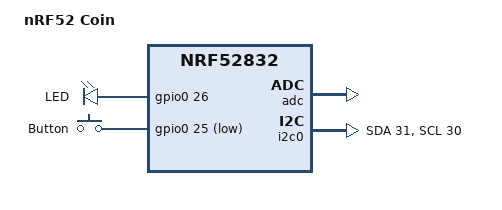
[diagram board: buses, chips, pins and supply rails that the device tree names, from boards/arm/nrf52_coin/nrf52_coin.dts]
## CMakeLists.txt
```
cmake_minimum_required(VERSION 3.8.2)

get_filename_component( ENV{ZEPHYR_BASE} "${CMAKE_SOURCE_DIR}/../zephyr" ABSOLUTE)
set( ENV{BOARD} nrf52_coin )
set( BOARD_ROOT ${CMAKE_SOURCE_DIR} )
set( ENV{ZEPHYR_TOOLCHAIN_VARIANT} zephyr )
set( ENV{ZEPHYR_SDK_INSTALL_DIR} /opt/zephyr-sdk/ )

include($ENV{ZEPHYR_BASE}/cmake/app/boilerplate.cmake NO_POLICY_SCOPE)

project(coin)
zephyr_include_directories(
  $ENV{ZEPHYR_BASE}/subsys/bluetooth/host
)


target_sources(app PRIVATE src/main.c src/kx022.c)
```

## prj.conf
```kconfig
# Incresed stack due to settings API usage
CONFIG_SYSTEM_WORKQUEUE_STACK_SIZE=2048

CONFIG_BT=y
CONFIG_BT_DEBUG_LOG=y
CONFIG_BT_SMP=y
CONFIG_BT_SIGNING=y
CONFIG_BT_PERIPHERAL=y
CONFIG_BT_GATT_DIS=y
CONFIG_BT_ATT_PREPARE_COUNT=5
CONFIG_BT_PRIVACY=y
CONFIG_BT_DEVICE_NAME="Zephyr"
CONFIG_BT_DEVICE_APPEARANCE=833

CONFIG_BT_SETTINGS=y
CONFIG_FLASH=y
CONFIG_FLASH_PAGE_LAYOUT=y
CONFIG_FLASH_MAP=y
CONFIG_FCB=y
CONFIG_SETTINGS=y
CONFIG_SETTINGS_FCB=y

CONFIG_I2C=y
CONFIG_I2C_0=y

CONFIG_BT_LL_SW_LEGACY=y

CONFIG_HAS_SEGGER_RTT=y
CONFIG_USE_SEGGER_RTT=y
CONFIG_RTT_CONSOLE=y
CONFIG_UART_CONSOLE=n
```

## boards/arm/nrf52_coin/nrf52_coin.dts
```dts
/*
 * Copyright (c) Maximilian Deubel
 *
 * SPDX-License-Identifier: Apache-2.0
 */

/dts-v1/;
#include <nordic/nrf52832_qfaa.dtsi>

/ {
	model = "nRF52 Coin";
	compatible = "maxd,nrf52_coin", "nordic,nrf52832-qfaa",
		     "nordic,nrf52832";

	chosen {
		zephyr,sram = &sram0;
		zephyr,flash = &flash0;
	};

	/* These aliases are provided for compatibility with samples */
	aliases {
		led0 = &led0;
		sw0 = &button0;
	};

	leds {
		compatible = "gpio-leds";
		led0: led_0 {
			gpios = <&gpio0 26 0>;
			label = "LED";
		};
	};

	buttons {
		compatible = "gpio-keys";
		button0: button_0 {
			gpios = <&gpio0 25 (GPIO_PUD_PULL_UP |
					    GPIO_INT_ACTIVE_LOW)>;
			label = "Button";
		};
	};
};

&adc {
	status ="okay";
};

&gpiote {
	status ="okay";
};

&gpio0 {
	status ="okay";
};

arduino_i2c: &i2c0 {
	status = "okay";
	sda-pin = <31>;
	scl-pin = <30>;
};

&flash0 {
	/*
	 * For more information, see:
	 * http://docs.zephyrproject.org/latest/guides/dts/index.html#flash-partitions
	 */
	partitions {
		compatible = "fixed-partitions";
		#address-cells = <1>;
		#size-cells = <1>;
		slot0_partition: partition@0 {
			label = "image-0";
			reg = <0x00000000 0x32000>;
		};

		storage_partition: partition@32000 {
			label = "storage";
			reg = <0x32000 0x00006000>;
		};
		/*
		 * REMEMBER TO UPDATE ADDRESS AND LENGTH IN prod/gen_bond.py
		 */
	};
};
```

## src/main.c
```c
#include <errno.h>
#include <zephyr.h>
#include <sys/printk.h>
#include <device.h>
#include <drivers/i2c.h>
#include <gpio.h>

#include <settings/settings.h>

#include <bluetooth/bluetooth.h>
#include <bluetooth/hci.h>
#include <bluetooth/conn.h>
#include <bluetooth/uuid.h>
#include <bluetooth/gatt.h>

#include <logging/log.h>

LOG_MODULE_REGISTER(app);

#include "kx022.h"

#define I2C_DEV "I2C_0"
#define LED_PORT DT_ALIAS_LED0_GPIOS_CONTROLLER
#define LED DT_ALIAS_LED0_GPIOS_PIN

static uint8_t batt_adv_bytes[] = {0x0f, 0x18, /* batt level UUID */
                                   0x00}; /* actual batt level */
static const struct bt_data ad[] = {
        BT_DATA_BYTES(BT_DATA_FLAGS, (BT_LE_AD_GENERAL | BT_LE_AD_NO_BREDR)),
        BT_DATA(BT_DATA_SVC_DATA16, batt_adv_bytes, sizeof(batt_adv_bytes))
};

static void bt_ready(int err) {
    if (err) {
        LOG_INF("Bluetooth init failed (err %d)", err);
        return;
    }

    LOG_INF("Bluetooth initialized");

    if (IS_ENABLED(CONFIG_SETTINGS)) {
        settings_load();
    }

    err = bt_le_adv_start(BT_LE_ADV_CONN_NAME, ad, ARRAY_SIZE(ad), NULL, 0);
    if (err) {
        LOG_INF("Advertising failed to start (err %d)", err);
        return;
    }

    LOG_INF("Advertising successfully started");
}

static u8_t led_state = 0;

static void kx022_int1(struct device *dev, struct gpio_callback *cb, u32_t pins) {
    ARG_UNUSED(dev);
    ARG_UNUSED(cb);
    ARG_UNUSED(pins);
    led_state = 1 - led_state;
    gpio_pin_write(dev, LED, led_state);
    LOG_INF("YEAH, the INT1 interrupt occurred.");
}

static struct gpio_callback kx022_int1_cb = {{0}};

void main(void) {
    struct device *i2c_dev = device_get_binding(I2C_DEV);
    if (!i2c_dev) {
        LOG_INF("I2C: Device driver not found.");
        return;
    }
    batt_adv_bytes[2] = kx022_verify_id(i2c_dev, KX022_ADDR_GND);
    LOG_INF("ID Verified? %d ", batt_adv_bytes[2]);
    kx022_init(i2c_dev, KX022_ADDR_GND);
    u8_t readout[6] = {0};
    while (1) {
        k_sleep(1000);
        kx022_read_acc(i2c_dev, KX022_ADDR_GND, readout);
        int16_t x = (readout[0] | (readout[1] << 8));
        int16_t y = (readout[2] | (readout[3] << 8));
        int16_t z = (readout[4] | (readout[5] << 8));
        x /= 409.6;
        y /= 409.6;
        z /= 409.6;
        LOG_INF("X: %d Y %d Z: %d ", x, y, z);
        //LOG_HEXDUMP_INF(readout, 6, "READOUT");
    }
}
```

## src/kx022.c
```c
#include "kx022.h"
#include "kx022_regs.h"

#include <logging/log.h>

LOG_MODULE_REGISTER(kx022);

void kx022_init(struct device *dev, u16_t addr) {
    // go into setup mode
    i2c_reg_write_byte(dev, addr, KX022_REG_CNTL1, 0);
    // set output data rate to 12.5Hz
    i2c_reg_write_byte(dev, addr, KX022_REG_ODCNTL, 0);
    // enable INT1 non-latching active-low
    i2c_reg_write_byte(dev, addr, KX022_REG_INC1, KX022_BIT_IEL1 | KX022_BIT_IEN1);
    // enable INT1 on data ready
    i2c_reg_write_byte(dev, addr, KX022_REG_INC4, KX022_BIT_DRDYI1);
    // set low-power (8-Bit resolution), sensitivity and enable sensor
    i2c_reg_write_byte(dev, addr, KX022_REG_CNTL1, KX022_BIT_PC1 | KX022_BIT_GSEL1 | KX022_BIT_RES);
    k_sleep(250);
}

bool kx022_verify_id(struct device *dev, u16_t addr) {
    u8_t id = 0;
    //read who-am-i value
    i2c_reg_read_byte(dev, addr, KX022_REG_Who_AM_I, &id);
    return KX022_WHO_AM_I_VAL == id;
}

void kx022_read_acc(struct device *dev, u16_t addr, u8_t *output) {
    i2c_burst_read(dev, addr, KX022_REG_XOUTL, output, 6);
}
```

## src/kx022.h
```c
#pragma once

#define KX022_ADDR_GND 0x1e
#define KX022_ADDR_VCC 0x1f

#include <zephyr.h>
#include <drivers/i2c.h>

// initialize sensor
void kx022_init(struct device *dev, u16_t addr);
// returns true if who-am-i register has expected value
bool kx022_verify_id(struct device *dev, u16_t addr);

// output has to be 6 bytes long
void kx022_read_acc(struct device *dev, u16_t addr, u8_t *output);
```

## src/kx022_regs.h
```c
#define KX022_REG_XHPL 0x00
#define KX022_REG_XHPH 0x01
#define KX022_REG_YHPL 0x02
#define KX022_REG_YHPH 0x03
#define KX022_REG_ZHPL 0x04
#define KX022_REG_ZHPH 0x05
#define KX022_REG_XOUTL 0x06
#define KX022_REG_XOUTH 0x07
#define KX022_REG_YOUTL 0x08
#define KX022_REG_YOUTH 0x09
#define KX022_REG_ZOUTL 0x0A
#define KX022_REG_ZOUTH 0x0B
#define KX022_REG_COTR 0x0C
#define KX022_REG_Who_AM_I 0x0F
#define KX022_REG_TSCP 0x10
#define KX022_REG_TSPP 0x11
#define KX022_REG_INS1 0x12
#define KX022_REG_INS2 0x13
#define KX022_REG_INS3 0x14
#define KX022_REG_STAT 0x15
#define KX022_REG_INT_REL 0x17
#define KX022_REG_CNTL1 0x18
#define KX022_REG_CNTL2 0x19
#define KX022_REG_CNTL3 0x1A
#define KX022_REG_ODCNTL 0x1B
#define KX022_REG_INC1 0x1C
#define KX022_REG_INC2 0x1D
#define KX022_REG_INC3 0x1E
#define KX022_REG_INC4 0x1F
#define KX022_REG_INC5 0x20
#define KX022_REG_INC6 0x21
#define KX022_REG_TILT_TIMER 0x22
#define KX022_REG_WUFC 0x23
#define KX022_REG_TDTRC 0x24
#define KX022_REG_TDTC 0x25
#define KX022_REG_TTH 0x26
#define KX022_REG_TTL 0x27
#define KX022_REG_FTD 0x28
#define KX022_REG_STD 0x29
#define KX022_REG_TLT 0x2A
#define KX022_REG_TWS 0x2B
#define KX022_REG_ATH 0x30
#define KX022_REG_TILT_ANGLE_LL 0x32
#define KX022_REG_TILT_ANGLE_HL 0x33
#define KX022_REG_HYST_SET 0x34
#define KX022_REG_LP_CNTL 0x35
#define KX022_REG_BUF_CNTL1 0x3A
#define KX022_REG_BUF_CNTL2 0x3B
#define KX022_REG_BUF_STATUS_1 0x3C
#define KX022_REG_BUF_STATUS_2 0x3D
#define KX022_REG_BUF_CLEAR 0x3E
#define KX022_REG_BUF_READ 0x3F
#define KX022_REG_SELF_TEST 0x60

// bits of KX022_REG_ODCNTL
#define KX022_BIT_OSA0 (1 << 0)
#define KX022_BIT_OSA1 (1 << 1)
#define KX022_BIT_OSA2 (1 << 2)
#define KX022_BIT_OSA3 (1 << 3)
#define KX022_BIT_LPRO (1 << 6)
#define KX022_BIT_IIR_BYPASS (1 << 7)

// bits of KX022_REG_CNTL1
#define KX022_BIT_TPE (1 << 0)
#define KX022_BIT_WUFE (1 << 1)
#define KX022_BIT_TDTE (1 << 2)
#define KX022_BIT_GSEL0 (1 << 3)
#define KX022_BIT_GSEL1 (1 << 4)
#define KX022_BIT_DRDYE (1 << 5)
#define KX022_BIT_RES (1 << 6)
#define KX022_BIT_PC1 (1 << 7)

// bits of KX022_REG_INC1
#define KX022_BIT_SPI3E (1 << 0)
#define KX022_BIT_STPOL (1 << 1)
#define KX022_BIT_IEL1 (1 << 3)
#define KX022_BIT_IEA1 (1 << 4)
#define KX022_BIT_IEN1 (1 << 5)

//bits of KX022_REG_INC2
#define KX022_BIT_ZPWUE (1 << 0)
#define KX022_BIT_ZNWUE (1 << 1)
#define KX022_BIT_YPWUE (1 << 2)
#define KX022_BIT_YNWUE (1 << 3)
#define KX022_BIT_XPWUE (1 << 4)
#define KX022_BIT_XNWUE (1 << 5)

//bits of KX022_REG_INC3
#define KX022_BIT_TFUM (1 << 0)
#define KX022_BIT_TFDM (1 << 1)
#define KX022_BIT_TUPM (1 << 2)
#define KX022_BIT_TDOM (1 << 3)
#define KX022_BIT_TRIM (1 << 4)
#define KX022_BIT_TLEM (1 << 5)

//bits of KX022_REG_INC4
#define KX022_BIT_TPI1 (1 << 0)
#define KX022_BIT_WUFI1 (1 << 1)
#define KX022_BIT_TDTI1 (1 << 2)
#define KX022_BIT_DRDYI1 (1 << 4)
#define KX022_BIT_WMI1 (1 << 5)
#define KX022_BIT_BFI1 (1 << 6)


#define KX022_WHO_AM_I_VAL 0x14
```
